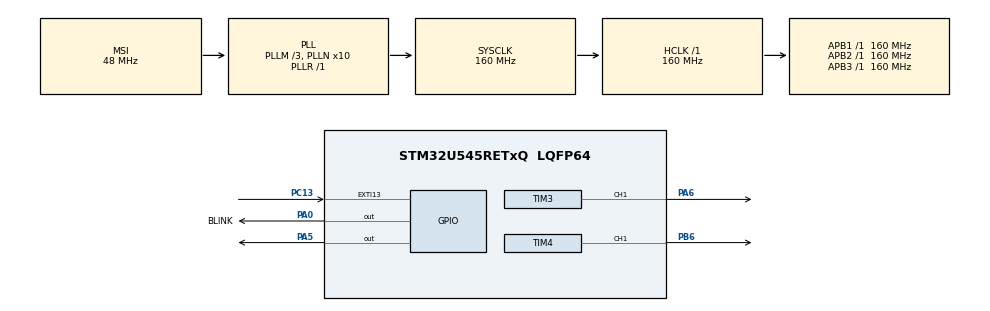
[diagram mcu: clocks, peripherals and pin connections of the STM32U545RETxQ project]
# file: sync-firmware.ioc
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CORTEX_M33_NS.userName=CORTEX_M33
GPDMA1.CIRCULARMODE_GPDMACH0=ENABLE
GPDMA1.DIRECTION_GPDMACH0=DMA_MEMORY_TO_PERIPH
GPDMA1.IPHANDLE_GPDMACH0-SIMPLEREQUEST_GPDMACH0=__NULL
GPDMA1.REQUEST_GPDMACH0=GPDMA1_REQUEST_TIM3_CH1
GPDMA1.SRCDATAWIDTH_GPDMACH0=DMA_SRC_DATAWIDTH_WORD
Mcu.Family=STM32U5
Mcu.Name=STM32U545RETxQ
Mcu.Package=LQFP64
NUCLEO-U545RE-Q.BUTTON=1
NUCLEO-U545RE-Q.LD2=true
NUCLEO-U545RE-Q.VCP=true
NVIC.EXTI13_IRQn=true\:0\:0\:false\:false\:true\:false\:true\:true
NVIC.GPDMA1_Channel0_IRQn=true\:0\:0\:false\:false\:true\:false\:true\:true
NVIC.PriorityGroup=NVIC_PRIORITYGROUP_4
NVIC.TIM3_IRQn=true\:0\:0\:false\:false\:true\:true\:true\:true
PA0.GPIO_Label=BLINK
PA0.Signal=GPIO_Output
PA5.Signal=GPIO_Output
PA6.GPIO_ModeDefaultPP=GPIO_MODE_AF_OD
PA6.Signal=S_TIM3_CH1
PB6.GPIO_ModeDefaultPP=GPIO_MODE_AF_OD
PB6.Signal=S_TIM4_CH1
PC13.Signal=GPXTI13
PWR.PowerMode=PWR_SMPS_SUPPLY
ProjectManager.HeapSize=0x200
ProjectManager.StackSize=0x400
ProjectManager.TargetToolchain=STM32CubeIDE
RCC.ADCFreq_Value=16000000
RCC.AHBFreq_Value=160000000
RCC.APB1Freq_Value=160000000
RCC.APB1TimFreq_Value=160000000
RCC.APB2Freq_Value=160000000
RCC.APB2TimFreq_Value=160000000
RCC.APB3Freq_Value=160000000
RCC.CortexFreq_Value=160000000
RCC.DACCLockSelectionVirtual=RCC_DAC1CLKSOURCE_LSI
RCC.DACCLockSelectionVirtualString=RCC_DAC1CLKSOURCE_LSI
RCC.EPOD_VALUE=48000000
RCC.HCLKFreq_Value=160000000
RCC.HSE_VALUE=16000000
RCC.HSI48_VALUE=48000000
RCC.HSI_VALUE=16000000
RCC.LSE_VALUE=32768
RCC.LSIDIV_VALUE=32000
RCC.MSIClockRange=RCC_MSIRANGE_0
RCC.MSI_VALUE=48000000
RCC.PLL1R=1
RCC.PLL2FRACN=0
RCC.PLL3FRACN=0
RCC.PLLFRACN=0
RCC.PLLM=3
RCC.PLLN=10
RCC.SYSCLKFreq_VALUE=160000000
RCC.SYSCLKSource=RCC_SYSCLKSOURCE_PLLCLK
RCC.USBFreq_Value=48000000
RCC.VCOOutputFreq_Value=160000000
SH.S_TIM3_CH1.0=TIM3_CH1,PWM Generation1 CH1
SH.S_TIM4_CH1.0=TIM4_CH1,PWM Generation1 CH1
TIM3.AutoReloadPreload=TIM_AUTORELOAD_PRELOAD_ENABLE
TIM3.Channel-Output\ Compare2\ No\ Output=TIM_CHANNEL_2
TIM3.Channel-PWM\ Generation1\ CH1=TIM_CHANNEL_1
TIM3.ClockDivision=TIM_CLOCKDIVISION_DIV1
TIM3.OCPolarity_1=TIM_OCPOLARITY_LOW
TIM3.PeriodNoDither=63
TIM3.Prescaler=159
TIM4.AutoReloadPreload=TIM_AUTORELOAD_PRELOAD_ENABLE
TIM4.Channel-PWM\ Generation1\ CH1=TIM_CHANNEL_1
TIM4.OCPolarity_1=TIM_OCPOLARITY_LOW
TIM4.PeriodNoDither=63
TIM4.Prescaler=159
VP_GPDMA1_VS_GPDMACH0.Mode=SIMPLEREQUEST_GPDMACH0
VP_ICACHE_VS_ICACHE.Mode=DirectMappedCache
VP_LPBAMQUEUE_VS_QUEUE.Mode=QUEUEMODE
VP_MEMORYMAP_VS_MEMORYMAP.Mode=CurAppReg
VP_NUCLEO-U545RE-Q_VS_BSP_COMMON.Mode=COMMON
VP_PWR_VS_LPOM.Mode=PowerOptimisation
VP_PWR_VS_SECSignals.Mode=Security/Privilege
VP_TIM3_VS_ClockSourceINT.Mode=Internal
VP_TIM3_VS_no_output2.Mode=Output Compare2 No Output
VP_TIM4_VS_ClockSourceINT.Mode=Internal
board=NUCLEO-U545RE-Q

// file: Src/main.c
/* USER CODE BEGIN Header */
/**
 ******************************************************************************
 * @file           : main.c
 * @brief          : Main program body
 ******************************************************************************
 * @attention
 *
 * Copyright (c) 2025 STMicroelectronics.
 * All rights reserved.
 *
 * This software is licensed under terms that can be found in the LICENSE file
 * in the root directory of this software component.
 * If no LICENSE file comes with this software, it is provided AS-IS.
 *
 ******************************************************************************
 */
/* USER CODE END Header */
#include "main.h"
#include "gpdma.h"
#include "icache.h"
#include "memorymap.h"
#include "tim.h"
#include "gpio.h"

/* USER CODE BEGIN Includes */
#include "vid.h"
/* USER CODE END Includes */

COM_InitTypeDef BspCOMInit;

/* USER CODE BEGIN PV */
vid_flow_t video;

/* USER CODE END PV */

void SystemClock_Config(void);
static void SystemPower_Config(void);

int main(void) {

	/* MCU Configuration--------------------------------------------------------*/

	/* Reset of all peripherals, Initializes the Flash interface and the Systick. */
	HAL_Init();

	/* Configure the System Power */
	SystemPower_Config();

	/* Configure the system clock */
	SystemClock_Config();

	/* Initialize all configured peripherals */
	MX_GPIO_Init();
	MX_GPDMA1_Init();
	MX_ICACHE_Init();
	MX_TIM3_Init();
	MX_TIM4_Init();
	/* USER CODE BEGIN 2 */
	vid_init(&video, 64, 10, &htim3, &htim4); //debug

	/* USER CODE END 2 */

	/* Initialize led */
	BSP_LED_Init(LED_GREEN);

	/* Initialize USER push-button, will be used to trigger an interrupt each time it's pressed.*/
	BSP_PB_Init(BUTTON_USER, BUTTON_MODE_EXTI);

	/* Initialize COM1 port (115200, 8 bits (7-bit data + 1 stop bit), no parity */
	BspCOMInit.BaudRate = 115200;
	BspCOMInit.WordLength = COM_WORDLENGTH_8B;
	BspCOMInit.StopBits = COM_STOPBITS_1;
	BspCOMInit.Parity = COM_PARITY_NONE;
	BspCOMInit.HwFlowCtl = COM_HWCONTROL_NONE;
	if (BSP_COM_Init(COM1, &BspCOMInit) != BSP_ERROR_NONE) {
		Error_Handler();
	}

	/* Infinite loop */
	while (1) {

	}
}

void SystemClock_Config(void) {
	RCC_OscInitTypeDef RCC_OscInitStruct = { 0 };
	RCC_ClkInitTypeDef RCC_ClkInitStruct = { 0 };

	/** Configure the main internal regulator output voltage
	 */
	if (HAL_PWREx_ControlVoltageScaling(PWR_REGULATOR_VOLTAGE_SCALE1)
			!= HAL_OK) {
		Error_Handler();
	}

	/** Initializes the CPU, AHB and APB buses clocks
	 */
	RCC_OscInitStruct.OscillatorType = RCC_OSCILLATORTYPE_MSI;
	RCC_OscInitStruct.MSIState = RCC_MSI_ON;
	RCC_OscInitStruct.MSICalibrationValue = RCC_MSICALIBRATION_DEFAULT;
	RCC_OscInitStruct.MSIClockRange = RCC_MSIRANGE_0;
	RCC_OscInitStruct.PLL.PLLState = RCC_PLL_ON;
	RCC_OscInitStruct.PLL.PLLSource = RCC_PLLSOURCE_MSI;
	RCC_OscInitStruct.PLL.PLLMBOOST = RCC_PLLMBOOST_DIV4;
	RCC_OscInitStruct.PLL.PLLM = 3;
	RCC_OscInitStruct.PLL.PLLN = 10;
	RCC_OscInitStruct.PLL.PLLP = 2;
	RCC_OscInitStruct.PLL.PLLQ = 2;
	RCC_OscInitStruct.PLL.PLLR = 1;
	RCC_OscInitStruct.PLL.PLLRGE = RCC_PLLVCIRANGE_1;
	RCC_OscInitStruct.PLL.PLLFRACN = 0;
	if (HAL_RCC_OscConfig(&RCC_OscInitStruct) != HAL_OK) {
		Error_Handler();
	}

	/** Initializes the CPU, AHB and APB buses clocks
	 */
	RCC_ClkInitStruct.ClockType = RCC_CLOCKTYPE_HCLK | RCC_CLOCKTYPE_SYSCLK
			| RCC_CLOCKTYPE_PCLK1 | RCC_CLOCKTYPE_PCLK2 | RCC_CLOCKTYPE_PCLK3;
	RCC_ClkInitStruct.SYSCLKSource = RCC_SYSCLKSOURCE_PLLCLK;
	RCC_ClkInitStruct.AHBCLKDivider = RCC_SYSCLK_DIV1;
	RCC_ClkInitStruct.APB1CLKDivider = RCC_HCLK_DIV1;
	RCC_ClkInitStruct.APB2CLKDivider = RCC_HCLK_DIV1;
	RCC_ClkInitStruct.APB3CLKDivider = RCC_HCLK_DIV1;

	if (HAL_RCC_ClockConfig(&RCC_ClkInitStruct, FLASH_LATENCY_4) != HAL_OK) {
		Error_Handler();
	}
}

/**
 * @brief Power Configuration
 * @retval None
 */
static void SystemPower_Config(void) {

	/*
	 * Switch to SMPS regulator instead of LDO
	 */
	if (HAL_PWREx_ConfigSupply(PWR_SMPS_SUPPLY) != HAL_OK) {
		Error_Handler();
	}
}

/* USER CODE BEGIN 4 */

void HAL_TIM_PeriodElapsedCallback(TIM_HandleTypeDef *htim) {
	vid_timerHsyncPECallback(&video, htim);
}

void HAL_TIM_OC_DelayElapsedCallback(TIM_HandleTypeDef *htim) {
	vid_timerHsyncOCCallback(&video, htim);
}

/* USER CODE END 4 */

void Error_Handler(void) {
	__disable_irq();
	while (1) {
	}
}
